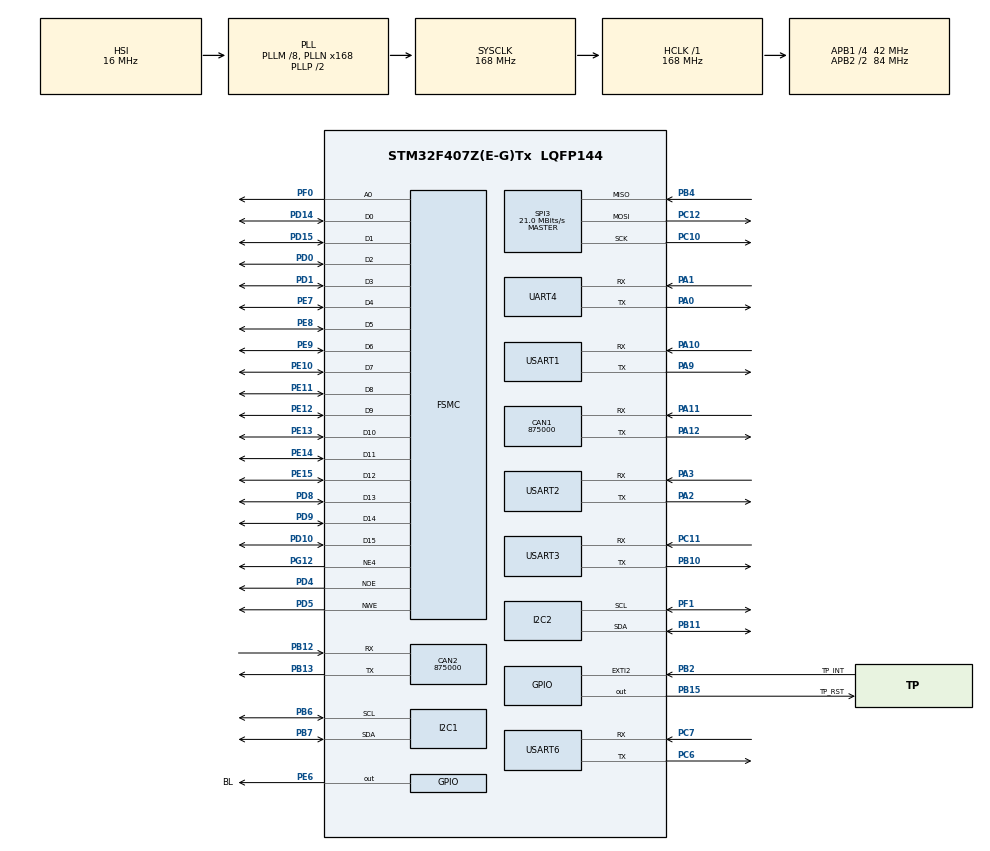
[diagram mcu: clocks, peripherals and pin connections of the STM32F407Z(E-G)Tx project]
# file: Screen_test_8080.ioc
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CAN1.CalculateBaudRate=875000
CAN1.CalculateTimeBit=1142
CAN1.CalculateTimeQuantum=380.95238095238096
CAN2.CalculateBaudRate=875000
CAN2.CalculateTimeBit=1142
CAN2.CalculateTimeQuantum=380.95238095238096
FREERTOS.Tasks01=defaultTask,24,128,StartDefaultTask,Default,NULL,Dynamic,NULL,NULL
FSMC.AddressSetupTime1=1
FSMC.BusTurnAroundDuration1=0
FSMC.DataSetupTime1=3
I2C2.I2C_Mode=I2C_Fast
Mcu.Family=STM32F4
Mcu.Name=STM32F407Z(E-G)Tx
Mcu.Package=LQFP144
NVIC.PriorityGroup=NVIC_PRIORITYGROUP_4
NVIC.TIM2_IRQn=true\:15\:0\:false\:false\:true\:false\:false\:true\:true
NVIC.TimeBase=TIM2_IRQn
NVIC.TimeBaseIP=TIM2
PA0-WKUP.Mode=Asynchronous
PA0-WKUP.Signal=UART4_TX
PA1.Mode=Asynchronous
PA1.Signal=UART4_RX
PA10.Mode=Asynchronous
PA10.Signal=USART1_RX
PA11.Mode=CAN_Activate
PA11.Signal=CAN1_RX
PA12.Mode=CAN_Activate
PA12.Signal=CAN1_TX
PA13.Mode=Serial_Wire
PA13.Signal=SYS_JTMS-SWDIO
PA14.Mode=Serial_Wire
PA14.Signal=SYS_JTCK-SWCLK
PA2.Mode=Asynchronous
PA2.Signal=USART2_TX
PA3.Mode=Asynchronous
PA3.Signal=USART2_RX
PA9.Mode=Asynchronous
PA9.Signal=USART1_TX
PB10.Mode=Asynchronous
PB10.Signal=USART3_TX
PB11.Mode=I2C
PB11.Signal=I2C2_SDA
PB12.Mode=CAN_Activate
PB12.Signal=CAN2_RX
PB13.Mode=CAN_Activate
PB13.Signal=CAN2_TX
PB15.GPIO_Label=TP_RST
PB15.PinState=GPIO_PIN_SET
PB15.Signal=GPIO_Output
PB2.GPIO_Label=TP_INT
PB2.GPIO_ModeDefaultEXTI=GPIO_MODE_IT_FALLING
PB2.GPIO_PuPd=GPIO_PULLUP
PB2.Signal=GPXTI2
PB4.Mode=Full_Duplex_Master
PB4.Signal=SPI3_MISO
PB6.Mode=I2C
PB6.Signal=I2C1_SCL
PB7.Mode=I2C
PB7.Signal=I2C1_SDA
PC10.Mode=Full_Duplex_Master
PC10.Signal=SPI3_SCK
PC11.Mode=Asynchronous
PC11.Signal=USART3_RX
PC12.Mode=Full_Duplex_Master
PC12.Signal=SPI3_MOSI
PC14-OSC32_IN.Mode=LSE-External-Oscillator
PC14-OSC32_IN.Signal=RCC_OSC32_IN
PC15-OSC32_OUT.Mode=LSE-External-Oscillator
PC15-OSC32_OUT.Signal=RCC_OSC32_OUT
PC6.Mode=Asynchronous
PC6.Signal=USART6_TX
PC7.Mode=Asynchronous
PC7.Signal=USART6_RX
PD0.Signal=FSMC_D2_DA2
PD1.Signal=FSMC_D3_DA3
PD10.Signal=FSMC_D15_DA15
PD14.Signal=FSMC_D0_DA0
PD15.Signal=FSMC_D1_DA1
PD4.Signal=FSMC_NOE
PD5.Signal=FSMC_NWE
PD8.Signal=FSMC_D13_DA13
PD9.Signal=FSMC_D14_DA14
PE10.Signal=FSMC_D7_DA7
PE11.Signal=FSMC_D8_DA8
PE12.Signal=FSMC_D9_DA9
PE13.Signal=FSMC_D10_DA10
PE14.Signal=FSMC_D11_DA11
PE15.Signal=FSMC_D12_DA12
PE6.GPIO_Label=BL
PE6.GPIO_Speed=GPIO_SPEED_FREQ_HIGH
PE6.Signal=GPIO_Output
PE7.Signal=FSMC_D4_DA4
PE8.Signal=FSMC_D5_DA5
PE9.Signal=FSMC_D6_DA6
PF0.Signal=FSMC_A0
PF1.Mode=I2C
PF1.Signal=I2C2_SCL
PG12.Mode=NorPsramChipSelect4_1
PG12.Signal=FSMC_NE4
PH0-OSC_IN.Mode=HSE-External-Oscillator
PH0-OSC_IN.Signal=RCC_OSC_IN
PH1-OSC_OUT.Mode=HSE-External-Oscillator
PH1-OSC_OUT.Signal=RCC_OSC_OUT
ProjectManager.HeapSize=0x200
ProjectManager.StackSize=0x400
ProjectManager.TargetToolchain=CMake
RCC.48MHZClocksFreq_Value=84000000
RCC.AHBFreq_Value=168000000
RCC.APB1CLKDivider=RCC_HCLK_DIV4
RCC.APB1Freq_Value=42000000
RCC.APB1TimFreq_Value=84000000
RCC.APB2CLKDivider=RCC_HCLK_DIV2
RCC.APB2Freq_Value=84000000
RCC.APB2TimFreq_Value=168000000
RCC.CortexFreq_Value=168000000
RCC.HCLKFreq_Value=168000000
RCC.HSE_VALUE=8000000
RCC.HSI_VALUE=16000000
RCC.PLLM=8
RCC.PLLN=168
RCC.SYSCLKFreq_VALUE=168000000
RCC.SYSCLKSource=RCC_SYSCLKSOURCE_PLLCLK
RCC.VCOOutputFreq_Value=336000000
SH.FSMC_A0.0=FSMC_A0,A0_1
SH.FSMC_D0_DA0.0=FSMC_D0,16b-d1
SH.FSMC_D10_DA10.0=FSMC_D10,16b-d1
SH.FSMC_D11_DA11.0=FSMC_D11,16b-d1
SH.FSMC_D12_DA12.0=FSMC_D12,16b-d1
SH.FSMC_D13_DA13.0=FSMC_D13,16b-d1
SH.FSMC_D14_DA14.0=FSMC_D14,16b-d1
SH.FSMC_D15_DA15.0=FSMC_D15,16b-d1
SH.FSMC_D1_DA1.0=FSMC_D1,16b-d1
SH.FSMC_D2_DA2.0=FSMC_D2,16b-d1
SH.FSMC_D3_DA3.0=FSMC_D3,16b-d1
SH.FSMC_D4_DA4.0=FSMC_D4,16b-d1
SH.FSMC_D5_DA5.0=FSMC_D5,16b-d1
SH.FSMC_D6_DA6.0=FSMC_D6,16b-d1
SH.FSMC_D7_DA7.0=FSMC_D7,16b-d1
SH.FSMC_D8_DA8.0=FSMC_D8,16b-d1
SH.FSMC_D9_DA9.0=FSMC_D9,16b-d1
SH.FSMC_NOE.0=FSMC_NOE,Lcd1
SH.FSMC_NWE.0=FSMC_NWE,Lcd1
SPI3.CalculateBaudRate=21.0 MBits/s
SPI3.Direction=SPI_DIRECTION_2LINES
SPI3.Mode=SPI_MODE_MASTER
SPI3.VirtualType=VM_MASTER
UART4.VirtualMode=Asynchronous
USART1.VirtualMode=VM_ASYNC
USART2.VirtualMode=VM_ASYNC
USART3.VirtualMode=VM_ASYNC
USART6.VirtualMode=VM_ASYNC
VP_FREERTOS_VS_CMSIS_V2.Mode=CMSIS_V2
VP_SYS_VS_tim2.Mode=TIM2
board=custom

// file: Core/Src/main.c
/* USER CODE BEGIN Header */
/**
  ******************************************************************************
  * @file           : main.c
  * @brief          : Main program body
  ******************************************************************************
  * @attention
  *
  * Copyright (c) 2026 STMicroelectronics.
  * All rights reserved.
  *
  * This software is licensed under terms that can be found in the LICENSE file
  * in the root directory of this software component.
  * If no LICENSE file comes with this software, it is provided AS-IS.
  *
  ******************************************************************************
  */
/* USER CODE END Header */
#include "main.h"
#include "cmsis_os.h"
#include "can.h"
#include "i2c.h"
#include "spi.h"
#include "usart.h"
#include "gpio.h"
#include "fsmc.h"

/* USER CODE BEGIN Includes */
#include "lcd8080.h"
/* USER CODE END Includes */

void SystemClock_Config(void);
void MX_FREERTOS_Init(void);

int main(void)
{

  /* MCU Configuration--------------------------------------------------------*/

  /* Reset of all peripherals, Initializes the Flash interface and the Systick. */
  HAL_Init();

  /* Configure the system clock */
  SystemClock_Config();

  /* Initialize all configured peripherals */
  MX_GPIO_Init();
  MX_CAN1_Init();
  MX_CAN2_Init();
  MX_FSMC_Init();
  MX_I2C1_Init();
  MX_I2C2_Init();
  MX_SPI3_Init();
  MX_UART4_Init();
  MX_USART1_UART_Init();
  MX_USART2_UART_Init();
  MX_USART3_UART_Init();
  MX_USART6_UART_Init();
  /* USER CODE BEGIN 2 */

  /* The module's LED input is active high.  Keep it off while CubeMX brings
   * up the GPIO, then enable it immediately before the ST7796 sequence. */
  HAL_GPIO_WritePin(BL_GPIO_Port, BL_Pin, GPIO_PIN_SET);
  LCD8080_Init();
  /* LVGL 和触摸在 lvglTask 中初始化，此后由同一个任务管理。 */

  /* USER CODE END 2 */

  /* Init scheduler */
  osKernelInitialize();  /* Call init function for freertos objects (in cmsis_os2.c) */
  MX_FREERTOS_Init();

  /* Start scheduler */
  osKernelStart();

  /* We should never get here as control is now taken by the scheduler */

  /* Infinite loop */
  while (1)
  {

  }
}

void SystemClock_Config(void)
{
  RCC_OscInitTypeDef RCC_OscInitStruct = {0};
  RCC_ClkInitTypeDef RCC_ClkInitStruct = {0};

  /** Configure the main internal regulator output voltage
  */
  __HAL_RCC_PWR_CLK_ENABLE();
  __HAL_PWR_VOLTAGESCALING_CONFIG(PWR_REGULATOR_VOLTAGE_SCALE1);

  /** Initializes the RCC Oscillators according to the specified parameters
  * in the RCC_OscInitTypeDef structure.
  */
  RCC_OscInitStruct.OscillatorType = RCC_OSCILLATORTYPE_HSI;
  RCC_OscInitStruct.HSIState = RCC_HSI_ON;
  RCC_OscInitStruct.HSICalibrationValue = RCC_HSICALIBRATION_DEFAULT;
  RCC_OscInitStruct.PLL.PLLState = RCC_PLL_ON;
  RCC_OscInitStruct.PLL.PLLSource = RCC_PLLSOURCE_HSI;
  RCC_OscInitStruct.PLL.PLLM = 8;
  RCC_OscInitStruct.PLL.PLLN = 168;
  RCC_OscInitStruct.PLL.PLLP = RCC_PLLP_DIV2;
  RCC_OscInitStruct.PLL.PLLQ = 4;
  if (HAL_RCC_OscConfig(&RCC_OscInitStruct) != HAL_OK)
  {
    Error_Handler();
  }

  /** Initializes the CPU, AHB and APB buses clocks
  */
  RCC_ClkInitStruct.ClockType = RCC_CLOCKTYPE_HCLK|RCC_CLOCKTYPE_SYSCLK
                              |RCC_CLOCKTYPE_PCLK1|RCC_CLOCKTYPE_PCLK2;
  RCC_ClkInitStruct.SYSCLKSource = RCC_SYSCLKSOURCE_PLLCLK;
  RCC_ClkInitStruct.AHBCLKDivider = RCC_SYSCLK_DIV1;
  RCC_ClkInitStruct.APB1CLKDivider = RCC_HCLK_DIV4;
  RCC_ClkInitStruct.APB2CLKDivider = RCC_HCLK_DIV2;

  if (HAL_RCC_ClockConfig(&RCC_ClkInitStruct, FLASH_LATENCY_5) != HAL_OK)
  {
    Error_Handler();
  }
}

void HAL_TIM_PeriodElapsedCallback(TIM_HandleTypeDef *htim)
{
  if (htim->Instance == TIM2)
  {
    HAL_IncTick();
  }
}

void Error_Handler(void)
{
  __disable_irq();
  while (1)
  {
  }
}

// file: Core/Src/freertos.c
/* USER CODE BEGIN Header */
/**
  ******************************************************************************
  * File Name          : freertos.c
  * Description        : Code for freertos applications
  ******************************************************************************
  * @attention
  *
  * Copyright (c) 2026 STMicroelectronics.
  * All rights reserved.
  *
  * This software is licensed under terms that can be found in the LICENSE file
  * in the root directory of this software component.
  * If no LICENSE file comes with this software, it is provided AS-IS.
  *
  ******************************************************************************
  */
/* USER CODE END Header */

#include "FreeRTOS.h"
#include "task.h"
#include "main.h"
#include "cmsis_os.h"

/* USER CODE BEGIN Includes */
#include "lvgl_port.h"
/* USER CODE END Includes */

/* USER CODE BEGIN Variables */
/* 12 KB 栈从 FreeRTOS 的 24 KB 堆中分配；LVGL 对象使用独立内存池。
 * widgets demo 切页时调用链较深，8 KB 栈容易触发异常。 */
static const osThreadAttr_t lvglTask_attributes = {
  .name = "lvglTask",
  .stack_size = 3072 * 4,
  .priority = (osPriority_t) osPriorityAboveNormal,
};
/* USER CODE END Variables */
/* Definitions for defaultTask */
osThreadId_t defaultTaskHandle;
const osThreadAttr_t defaultTask_attributes = {
  .name = "defaultTask",
  .stack_size = 128 * 4,
  .priority = (osPriority_t) osPriorityNormal,
};

void StartDefaultTask(void *argument);

void MX_FREERTOS_Init(void); /* (MISRA C 2004 rule 8.1) */

void MX_FREERTOS_Init(void) {

  /* Create the thread(s) */
  /* creation of defaultTask */
  defaultTaskHandle = osThreadNew(StartDefaultTask, NULL, &defaultTask_attributes);

  /* USER CODE BEGIN RTOS_THREADS */
  /* add threads, ... */
  if (osThreadNew(LVGL_Port_Task, NULL, &lvglTask_attributes) == NULL) {
    Error_Handler();
  }
  /* USER CODE END RTOS_THREADS */

}

void StartDefaultTask(void *argument)
{
  for(;;)
  {
    osDelay(1);
  }
}
